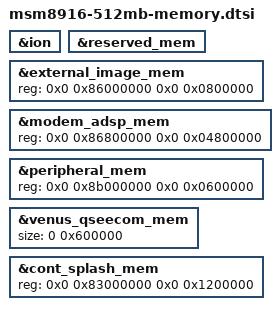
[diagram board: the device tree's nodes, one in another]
/* Copyright (c) 2014, The Linux Foundation. All rights reserved.
 *
 * This program is free software; you can redistribute it and/or modify
 * it under the terms of the GNU General Public License version 2 and
 * only version 2 as published by the Free Software Foundation.
 *
 * This program is distributed in the hope that it will be useful,
 * but WITHOUT ANY WARRANTY; without even the implied warranty of
 * MERCHANTABILITY or FITNESS FOR A PARTICULAR PURPOSE.  See the
 * GNU General Public License for more details.
 */

#include "msm8916-memory.dtsi"

&ion {
	/delete-node/ qcom,ion-heap@8;
};

&reserved_mem {
	/delete-node/ mba_mem;
	/delete-node/ secure_mem;
};

&external_image_mem {
	reg = <0x0 0x86000000 0x0 0x0800000>;
};

&modem_adsp_mem {
	reg = <0x0 0x86800000 0x0 0x04800000>;
};

&peripheral_mem {
	reg = <0x0 0x8b000000 0x0 0x0600000>;
};

&venus_qseecom_mem {
	size = <0 0x600000>;
};

&cont_splash_mem {
	reg = <0x0 0x83000000 0x0 0x1200000>;
};
